# R7FA2A2AD register map
Vendor: Renesas Electronics Corporation; Series: RA2A2; File version: 1.20.02
CPU: CM23 r1p0, little endian, MPU, no FPU, VTOR, 2 interrupt priority bits, 32 interrupts
Registers are 8-bit, read-write, reset 0x0 unless marked. A register's access mark holds for its fields unless they carry their own. Offsets are from the block's base; [hi:lo] are bit positions.

## FLCN — Flash I/O Registers
Base 0x407EC000
0x90 DFLCTL — Data Flash Control Register
  [0] DFLEN — Data Flash Access Enable
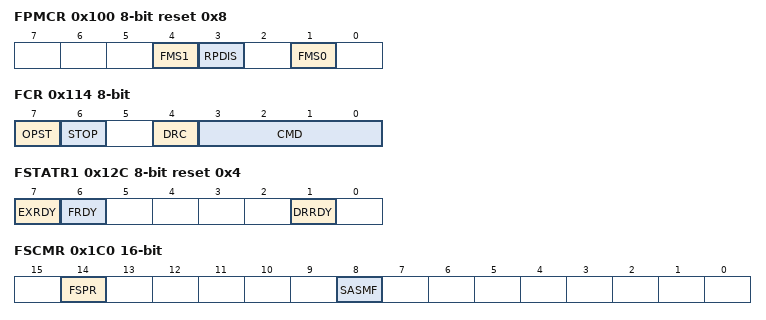
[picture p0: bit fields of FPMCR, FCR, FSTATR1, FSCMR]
0x100 FPMCR reset 0x8 — Flash P/E Mode Control Register
  [4] FMS1 — Flash Operating Mode Select 1
  [3] RPDIS — Code Flash P/E Disable
  [1] FMS0 — Flash Operating Mode Select 0
0x104 FASR — Flash Area Select Register
  [0] EXS — Extra Area Select
0x108 FSARL 16-bit — Flash Processing Start Address Register L
  [15:0] FSARL — Flash Processing Start Address L
0x110 FSARH 16-bit — Flash Processing Start Address Register H
  [15:0] FSARH — Flash Processing Start Address H
0x114 FCR — Flash Control Register
  [7] OPST — Processing Start
  [6] STOP — Forced Processing Stop
  [4] DRC — Data Read Completion
  [3:0] CMD — Software Command Setting
0x118 FEARL 16-bit — Flash Processing End Address Register L
  [15:0] FEARL — Flash Processing End Address L
0x120 FEARH 16-bit — Flash Processing End Address Register H
  [15:0] FEARH — Flash Processing End Address H
0x124 FRESETR — Flash Reset Register
  [0] FRESET — Software reset of the registers
0x12C FSTATR1 ro reset 0x4 — Flash Status Register 1
  [7] EXRDY — Extra Area Ready Flag
  [6] FRDY — Flash Ready Flag
  [1] DRRDY — Data Read Ready Flag
0x130 FWBL0 16-bit — Flash Write Buffer Register L0
  [15:0] WDATA — Flash Write Buffer L0
0x138 FWBH0 16-bit — Flash Write Buffer Register H0
  [15:0] WDATA — Flash Write Buffer H0
0x180 FPR reset not defined — Protection Unlock Register
  [7:0] FPR — Protection Unlock
0x184 FPSR ro — Protection Unlock Status Register
  [0] PERR — Protect Error Flag
0x188 FRBL0 16-bit ro — Flash Read Buffer Register L0
  [15:0] RDATA — Flash Read Buffer L0
0x190 FRBH0 16-bit ro — Flash Read Buffer Register H0
  [15:0] RDATA — Flash Read Buffer H0
0x1C0 FSCMR 16-bit ro (reset mask 0xB8FF) — Flash Startup Setting Monitor Register
  [14] FSPR — Access Window Protection Flag
  [8] SASMF — Startup Area Setting Monitor Flag
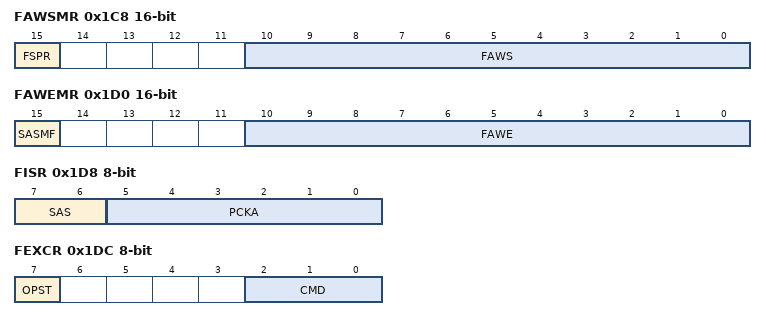
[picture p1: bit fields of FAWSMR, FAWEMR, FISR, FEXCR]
0x1C8 FAWSMR 16-bit ro (reset mask 0xF800) — Flash Access Window Start Address Monitor Register
  [15] FSPR — Access Window Protection Flag
  [10:0] FAWS — Access Window Start Address
0x1D0 FAWEMR 16-bit ro (reset mask 0xF800) — Flash Access Window End Address Monitor Register
  [15] SASMF — Startup Area Setting Monitor Flag
  [10:0] FAWE — Access Window End Address
0x1D8 FISR — Flash Initial Setting Register
  [7:6] SAS — Startup Area Select
  [5:0] PCKA — Flash,IF Clock Notification
0x1DC FEXCR — Flash Extra Area Control Register
  [7] OPST — Processing Start
  [2:0] CMD — Software Command Setting
0x1E0 FEAML 16-bit — Flash Error Address Monitor Register L
0x1E8 FEAMH 16-bit — Flash Error Address Monitor Register H
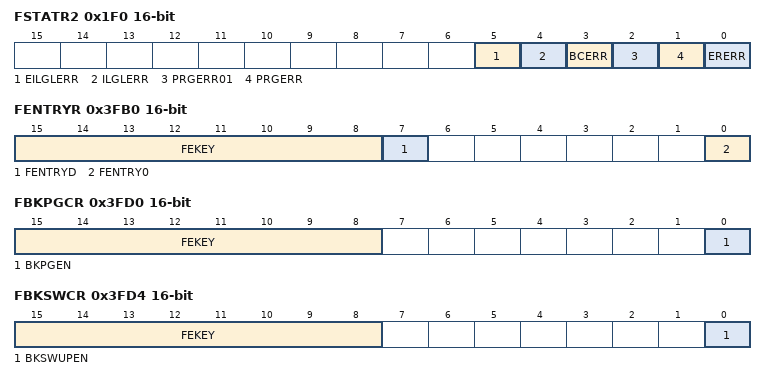
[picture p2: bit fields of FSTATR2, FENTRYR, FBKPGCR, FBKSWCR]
0x1F0 FSTATR2 16-bit ro — Flash Status Register 2
  [5] EILGLERR — Extra Area Illegal Command Error Flag
  [4] ILGLERR — Illegal Command Error Flag
  [3] BCERR — Blank Check Error Flag
  [2] PRGERR01 — Program Error Flag 01
  [1] PRGERR — Program Error Flag
  [0] ERERR — Erase Error Flag
0x228 TSCDR 32-bit ro — Temperature Sensor Calibration Data Register
  [15:0] TSCDR — Temperature Sensor Calibration Data
0x370 FCTLFR 32-bit (reset mask 0xFFFFFFF8) — Flash Control Flag Register
  [2:0] BANKSWP — Bank Swap Setting
0x3FB0 FENTRYR 16-bit — Flash P/E Mode Entry Register
  [15:8] FEKEY wo — Key Code
  [7] FENTRYD — Data Flash P/E Mode Entry
  [0] FENTRY0 — Code Flash P/E Mode Entry 0
0x3FC4 FLDWAITR — Memory Wait Cycle Control Register for Data Flash
  [0] FLDWAIT1 — Memory Wait Cycle Select for Data Flash
0x3FC8 PFBER — Prefetch Buffer Enable Register
  [0] PFBE — Prefetch Buffer Enable bit
0x3FD0 FBKPGCR 16-bit — Flash Bank Program Control Register
  [15:8] FEKEY wo — Key Code
  [0] BKPGEN — Bank Programming Setting Enable
0x3FD4 FBKSWCR 16-bit — Flash Bank Swap Control Register
  [15:8] FEKEY wo — Key Code
  [0] BKSWUPEN — Bank Swap Update Enable
